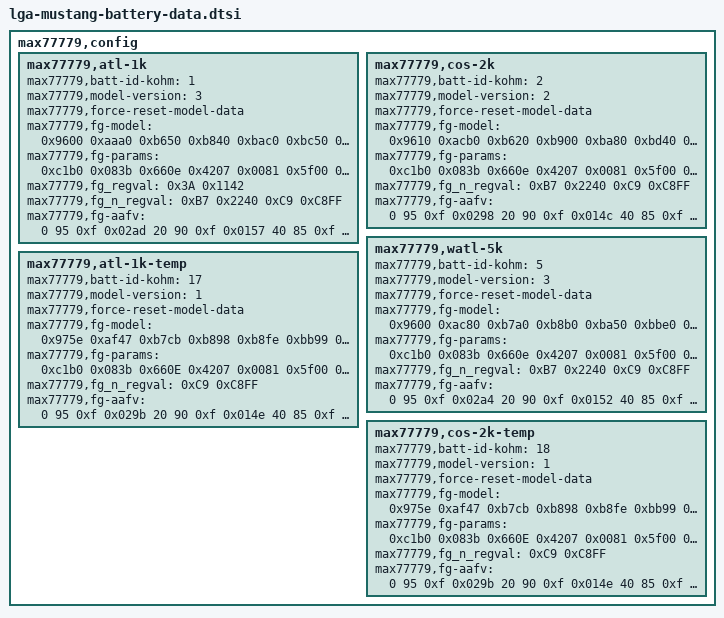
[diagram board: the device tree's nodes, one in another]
// SPDX-License-Identifier: GPL-2.0-only
/*
 * Battery device tree entries
 *
 * Copyright 2024 Google LLC
 *
 */

max77779,config {

	/* MT5_ATL_EVT1p1_G001.ini.txt, b/408496479#comment1 */
	max77779,atl-1k {
		max77779,batt-id-kohm = <1>;
		max77779,model-version = <3>;
		max77779,force-reset-model-data;
		max77779,fg-model = /bits/ 16 <
			0x9600 0xaaa0 0xb650 0xb840 0xbac0 0xbc50 0xbdb0 0xbf70
			0xc240 0xc5d0 0xc970 0xcd40 0xd0f0 0xd460 0xd8c0 0xdf30
			0x0030 0x0110 0x09b0 0x0c80 0x11e0 0x1500 0x1440 0x0d70
			0x0870 0x07f0 0x06d0 0x06c0 0x06c0 0x06b0 0x0650 0x0650
		>;
		max77779,fg-params = /bits/ 16 <
			/* 0x00C0 */	0xc1b0	/* nnvcfg0 */
			/* 0x00B6 */	0x083b	/* nrelaxcfg */
			/* 0x009F */	0x660e	/* nLearnCFG */
			/* 0x000C */	0x4207	/* Config */
			/* 0x00AB */	0x0081	/* Config2 */
			/* 0x00BC */	0x5f00	/* nFullSOCThr */
			/* 0x00A9 */	0x085a	/* nfullcaprep */
			/* 0x00B3 */	0x085a	/* ndesigncap */
			/* 0x0046 */	0x0c80	/* dPacc */
			/* 0x00A5 */	0x085a	/* nfullcapnom */
			/* 0x00C6 */	0xa55a	/* nVEmpty */
			/* 0x00A0 */	0x2d06	/* nQRTable00 */
			/* 0x00A1 */	0x1402	/* nQRTable10 */
			/* 0x00A2 */	0x0782	/* nQRTable20 */
			/* 0x00A3 */	0x0582	/* nQRTable30 */
			/* 0x00A6 */	0x0410	/* nRCOMP0 */
			/* 0x00A7 */	0x0a02	/* nTempCo */
			/* 0x009C */	0x02ad	/* nichgterm */
			/* 0x00B2 */	0x3870	/* nmisccfg */
			/* 0x009E */	0x0400	/* nModelCfg */
			/* 0x00CA */	0xc8ff	/* nThermCfg */
			/* 0x009D */	0xcea4	/* nFilterCfg */
		>;
		max77779,fg_regval = /bits/ 16 <
			0x3A 0x1142    /* SOCHold */
		>;
		max77779,fg_n_regval = /bits/ 16 <
			0xB7 0x2240	/* nConvgCfg */
			0xC9 0xC8FF	/* nThermCfg2 Register */
		>;
		max77779,fg-aafv = /bits/ 32 <
			  0   95  0xf  0x02ad
			 20   90  0xf  0x0157
			 40   85  0xf  0x0157
			 60   80  0xf  0x0157
			 80   75  0xf  0x0157
			100   70  0xf  0x0157
		>;
	};

	/* MT5_COS_3753_001_G1.ini.txt.overlay, b/377556072#comment2 */
	max77779,cos-2k {
		max77779,batt-id-kohm = <2>;
		max77779,model-version = <2>;
		max77779,force-reset-model-data;
		max77779,fg-model = /bits/ 16 <
			0x9610 0xacb0 0xb620 0xb900 0xba80 0xbd40 0xc030 0xc300
			0xc680 0xca50 0xce10 0xcf00 0xd200 0xd5c0 0xd8c0 0xdfb0
			0x0040 0x0210 0x08b0 0x0c20 0x0ef0 0x0eb0 0x0ff0 0x07e0
			0x06b0 0x06f0 0x0890 0x06b0 0x05f0 0x07e0 0x06f0 0x06f0
		>;
		max77779,fg-params = /bits/ 16 <
			/* 0x00C0 */	0xc1b0	/* nnvcfg0 */
			/* 0x00B6 */	0x083b	/* nrelaxcfg */
			/* 0x009F */	0x660e	/* nLearnCFG */
			/* 0x000C */	0x4207	/* Config */
			/* 0x00AB */	0x0081	/* Config2 */
			/* 0x00BC */	0x5f00	/* nFullSOCThr */
			/* 0x00A9 */	0x084a	/* nfullcaprep */
			/* 0x00B3 */	0x084a	/* ndesigncap */
			/* 0x0046 */	0x0c80	/* dPacc */
			/* 0x00A5 */	0x084a	/* nfullcapnom */
			/* 0x00C6 */	0xa55a	/* nVEmpty */
			/* 0x00A0 */	0x1e0c	/* nQRTable00 */
			/* 0x00A1 */	0x0f06	/* nQRTable10 */
			/* 0x00A2 */	0x0784	/* nQRTable20 */
			/* 0x00A3 */	0x0504	/* nQRTable30 */
			/* 0x00A6 */	0x0380	/* nRCOMP0 */
			/* 0x00A7 */	0x1402	/* nTempCo */
			/* 0x009C */	0x0298	/* nichgterm */
			/* 0x00B2 */	0x3870	/* nmisccfg */
			/* 0x009E */	0x0400	/* nModelCfg */
			/* 0x00CA */	0xc8ff	/* nThermCfg */
			/* 0x009D */	0xcea4	/* nFilterCfg */
		>;
		max77779,fg_n_regval = /bits/ 16 <
			0xB7 0x2240	/* nConvgCfg */
			0xC9 0xC8FF	/* nThermCfg2 Register */
		>;
		max77779,fg-aafv = /bits/ 32 <
			  0   95  0xf  0x0298
			 20   90  0xf  0x014c
			 40   85  0xf  0x014c
			 60   80  0xf  0x014c
			 80   75  0xf  0x014c
			100   70  0xf  0x014c
		>;
	};

	/* MT5W_ATL_ASIS_002_G2.ini.txt.overlay, b/419389737#comment3 */
	max77779,watl-5k {
		max77779,batt-id-kohm = <5>;
		max77779,model-version = <3>;
		max77779,force-reset-model-data;
		max77779,fg-model = /bits/ 16 <
			0x9600 0xac80 0xb7a0 0xb8b0 0xba50 0xbbe0 0xbdc0 0xc010
			0xc1c0 0xc560 0xc9d0 0xcbe0 0xd0f0 0xd4d0 0xdb30 0xdfe0
			0x0020 0x0150 0x10f0 0x0d90 0x0e10 0x13a0 0x15f0 0x1070
			0x0840 0x0760 0x0890 0x06d0 0x0650 0x0720 0x0480 0x0480
		>;
		max77779,fg-params = /bits/ 16 <
			/* 0x00C0 */	0xc1b0	/* nnvcfg0 */
			/* 0x00B6 */	0x083b	/* nrelaxcfg */
			/* 0x009F */	0x660e	/* nLearnCFG */
			/* 0x000C */	0x4207	/* Config */
			/* 0x00AB */	0x0081	/* Config2 */
			/* 0x00BC */	0x5f00	/* nFullSOCThr */
			/* 0x00A9 */	0x0841	/* nfullcaprep */
			/* 0x00B3 */	0x0841	/* ndesigncap */
			/* 0x0046 */	0x0c80	/* dPacc */
			/* 0x00A5 */	0x0841	/* nfullcapnom */
			/* 0x00C6 */	0xa55a	/* nVEmpty */
			/* 0x00A0 */	0x3606	/* nQRTable00 */
			/* 0x00A1 */	0x1700	/* nQRTable10 */
			/* 0x00A2 */	0x0780	/* nQRTable20 */
			/* 0x00A3 */	0x0680	/* nQRTable30 */
			/* 0x00A6 */	0x0500	/* nRCOMP0 */
			/* 0x00A7 */	0x0902	/* nTempCo */
			/* 0x009C */	0x02a4	/* nichgterm */
			/* 0x00B2 */	0x3870	/* nmisccfg */
			/* 0x009E */	0x0400	/* nModelCfg */
			/* 0x00CA */	0xc8ff	/* nThermCfg */
			/* 0x009D */	0xcea4	/* nFilterCfg */
		>;
		max77779,fg_n_regval = /bits/ 16 <
			0xB7 0x2240	/* nConvgCfg */
			0xC9 0xC8FF	/* nThermCfg2 Register */
		>;
		max77779,fg-aafv = /bits/ 32 <
			  0   95  0xf  0x02a4
			 20   90  0xf  0x0152
			 40   85  0xf  0x0152
			 60   80  0xf  0x0152
			 80   75  0xf  0x0152
			100   70  0xf  0x0152
		>;
	};

	/* BC79_MT5_2mOhm_ATL_3501_RC2_Proxy.INI, b/342241505#comment4 */
	max77779,atl-1k-temp {
		max77779,batt-id-kohm = <17>;
		max77779,model-version = <1>;
		max77779,force-reset-model-data;
		max77779,fg-model = /bits/ 16 <
			0x975e 0xaf47 0xb7cb 0xb898 0xb8fe 0xbb99 0xbc8d 0xbeae
			0xc08e 0xc2df 0xc8d2 0xce54 0xd265 0xd697 0xdb99 0xde9b
			0x0050 0x0170 0x0ec0 0x22b0 0x0c40 0x1260 0x1310 0x1200
			0x0e60 0x07e0 0x06c0 0x06f0 0x06b0 0x07d0 0x05b0 0x05b0
		>;
		max77779,fg-params = /bits/ 16 <
			/* 0x00C0 */	0xc1b0	/* nNVCfg0 */
			/* 0x00B6 */	0x083b	/* RelaxCFG */
			/* 0x009F */	0x660E	/* nLearnCFG */
			/* 0x000C */	0x4207	/* Config */
			/* 0x00AB */	0x0081	/* Config2 */
			/* 0x00BC */	0x5f00	/* nFullSOCthr */
			/* 0x00A9 */	0x0820	/* nFullCAPRep */
			/* 0x00B3 */	0x0820	/* nDesignCap */
			/* 0x0046 */	0x0C80	/* dPacc */
			/* 0x00A5 */	0x0820	/* nFullCAPNom */
			/* 0x00C6 */	0xa55a	/* nV_empty */
			/* 0x00A0 */	0x3382	/* nQRTable00 */
			/* 0x00A1 */	0x1700	/* nQRTable10 */
			/* 0x00A2 */	0x0780	/* nQRTable20 */
			/* 0x00A3 */	0x0501	/* nQRTable30 */
			/* 0x00A6 */	0x0600	/* nRCOMP0 */
			/* 0x00A7 */	0x1670	/* nTempCo */
			/* 0x009C */	0x029B	/* nIChgTerm */
			/* 0x00B2 */	0x3870	/* nMiscCFG */
			/* 0x009E */	0x0400	/* nModelCfg */
			/* 0x00CA */	0xC8FF	/* nThermCfg */
			/* 0x009D */	0xCEA4	/* nFilterCfg */
		>;
		max77779,fg_n_regval = /bits/ 16 <
			0xC9 0xC8FF    /* nThermCfg2 Register */
		>;
		max77779,fg-aafv = /bits/ 32 <
			  0   95  0xf  0x029b
			 20   90  0xf  0x014e
			 40   85  0xf  0x014e
			 60   80  0xf  0x014e
			 80   75  0xf  0x014e
			100   70  0xf  0x014e
		>;
	};

	/* BC79_MT5_2mOhm_COS_3501_RC2_Proxy.INI, b/342241505#comment4 */
	max77779,cos-2k-temp {
		max77779,batt-id-kohm = <18>;
		max77779,model-version = <1>;
		max77779,force-reset-model-data;
		max77779,fg-model = /bits/ 16 <
			0x975e 0xaf47 0xb7cb 0xb898 0xb8fe 0xbb99 0xbc8d 0xbeae
			0xc08e 0xc2df 0xc8d2 0xce54 0xd265 0xd697 0xdb99 0xde9b
			0x0050 0x0170 0x0ec0 0x22b0 0x0c40 0x1260 0x1310 0x1200
			0x0e60 0x07e0 0x06c0 0x06f0 0x06b0 0x07d0 0x05b0 0x05b0
		>;
		max77779,fg-params = /bits/ 16 <
			/* 0x00C0 */	0xc1b0	/* nNVCfg0 */
			/* 0x00B6 */	0x083b	/* RelaxCFG */
			/* 0x009F */	0x660E	/* nLearnCFG */
			/* 0x000C */	0x4207	/* Config */
			/* 0x00AB */	0x0081	/* Config2 */
			/* 0x00BC */	0x5f00	/* nFullSOCthr */
			/* 0x00A9 */	0x0820	/* nFullCAPRep */
			/* 0x00B3 */	0x0820	/* nDesignCap */
			/* 0x0046 */	0x0C80	/* dPacc */
			/* 0x00A5 */	0x0820	/* nFullCAPNom */
			/* 0x00C6 */	0xa55a	/* nV_empty */
			/* 0x00A0 */	0x3382	/* nQRTable00 */
			/* 0x00A1 */	0x1700	/* nQRTable10 */
			/* 0x00A2 */	0x0780	/* nQRTable20 */
			/* 0x00A3 */	0x0501	/* nQRTable30 */
			/* 0x00A6 */	0x0600	/* nRCOMP0 */
			/* 0x00A7 */	0x1670	/* nTempCo */
			/* 0x009C */	0x029B	/* nIChgTerm */
			/* 0x00B2 */	0x3870	/* nMiscCFG */
			/* 0x009E */	0x0400	/* nModelCfg */
			/* 0x00CA */	0xC8FF	/* nThermCfg */
			/* 0x009D */	0xCEA4	/* nFilterCfg */
		>;
		max77779,fg_n_regval = /bits/ 16 <
			0xC9 0xC8FF    /* nThermCfg2 Register */
		>;
		max77779,fg-aafv = /bits/ 32 <
			  0   95  0xf  0x029b
			 20   90  0xf  0x014e
			 40   85  0xf  0x014e
			 60   80  0xf  0x014e
			 80   75  0xf  0x014e
			100   70  0xf  0x014e
		>;
	};
};
